# PY32F032xx register map
Vendor: Puya; Series: PY32F0; File version: 1.0.0
CPU: CM0+ r0p1, little endian, no MPU, no FPU, 4 interrupt priority bits
Registers are 32-bit, read-write, reset 0x0 unless marked. A register's access mark holds for its fields unless they carry their own. Offsets are from the block's base; [hi:lo] are bit positions.

## RTC — Real time clock
Base 0x40002800
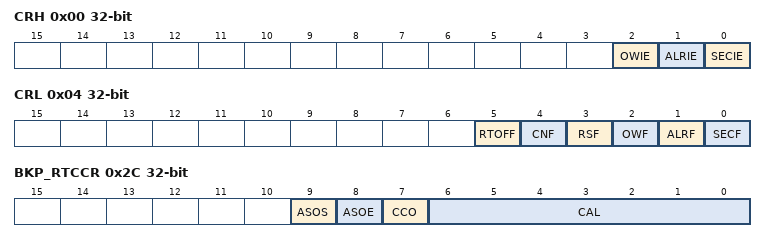
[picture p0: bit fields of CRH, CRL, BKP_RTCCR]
0x00 CRH — RTC Control Register High
  [2] OWIE — Overflow interrupt allow bits
  [1] ALRIE — Alarm interrupt allowed bits
  [0] SECIE — Seconds interrupt allowed bits
0x04 CRL — RTC Control Register Low
  [5] RTOFF ro — RTC operation OFF
  [4] CNF — Configuration flag
  [3] RSF — Registers synchronized flag
  [2] OWF — Overflow flag
  [1] ALRF — Alarm flag
  [0] SECF — Second flag
0x08 PRLH — RTC Prescaler Load Register High
  [5:0] PRL — RTC prescaler reload value high
0x0C PRLL — RTC Prescaler Load Register Low
  [15:0] PRL — RTC prescaler reload value high
0x10 DIVH — RTC Prescaler Divider Register High
  [3:0] RTC_DIV ro — RTC clock divider
    1=0; 2=1; 4=2; 8=3
0x14 DIVL — RTC Prescaler Divider Register Low
  [15:0] RTC_DIV ro — RTC clock divider
0x18 CNTH — RTC Counter Register High
  [15:0] RTC_CNT — RTC core counter
0x1C CNTL — RTC Counter Register Low
  [15:0] RTC_CNT — RTC core counter
0x20 ALRH — RTC Alarm Register High
  [15:0] ALR — RTC alarm value
0x24 ALRL — RTC Alarm Register Low
  [15:0] ALR — RTC alarm value
0x2C BKP_RTCCR
  [9] ASOS — Seconds/alarm pulse output select bits
  [8] ASOE — Seconds/alarm pulse output enable bit
  [7] CCO — Calibrate the clock output bits
  [6:0] CAL — Calibration value

## SPI1 — Serial peripheral interface
Base 0x40013000
Same registers: SPI2 0x40003800
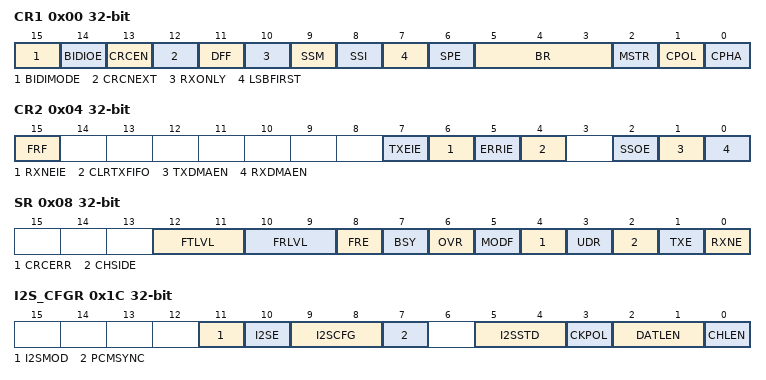
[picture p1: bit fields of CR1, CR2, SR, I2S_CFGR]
0x00 CR1 — control register 1
  [15] BIDIMODE — Bidirectional data mode enable
  [14] BIDIOE — Output enable in bidirectional mode
  [13] CRCEN — Hardware CRC calculation enable
  [12] CRCNEXT — Transmit CRC next
  [11] DFF — Data frame format
  [10] RXONLY — Receive only
  [9] SSM — Software slave management
  [8] SSI — Internal slave select
  [7] LSBFIRST — Frame Format
  [6] SPE — SPI Enable
  [5:3] BR — Baud Rate Control
    1=0; 2=1; 4=2
  [2] MSTR — Master Selection
  [1] CPOL — Clock Polarity
  [0] CPHA — Clock Phase
0x04 CR2 — control register 2
  [15] FRF
  [7] TXEIE — Tx buffer Empty Interrupt Enable
  [6] RXNEIE — RX buffer Not Empty Interrupt Enable
  [5] ERRIE — Error Interrupt Enable
  [4] CLRTXFIFO — Clear FIFO
  [2] SSOE — SS Output Enable
  [1] TXDMAEN — Tx buffer DMA enable
  [0] RXDMAEN — Rx buffer DMA enable
0x08 SR — status register
  [12:11] FTLVL ro — FIFO Transmission Level
    1=0; 2=1
  [10:9] FRLVL ro — FIFO Reception Level
    1=0; 2=1
  [8] FRE ro
  [7] BSY ro — Busy flag
  [6] OVR ro — Overrun flag
  [5] MODF — Mode fault
  [4] CRCERR — CRC error flag
  [3] UDR ro — Underrun flag
  [2] CHSIDE ro — Channel side
  [1] TXE ro — Transmit buffer Empty
  [0] RXNE ro — Receive buffer Not Empty
0x0C DR — data register
  [15:0] DR — Data Register
0x10 CRCPR — CRC polynomial register
  [15:0] CRCPOLY
0x14 RXCRCR
  [15:0] RXCRC — rcv crc reg
0x18 TXCRCR
  [15:0] TXCRC ro — tx crc reg
0x1C I2S_CFGR
  [11] I2SMOD — I2S mode selection
  [10] I2SE — I2S enable
  [9:8] I2SCFG — I2S configuration mode
    1=0; 2=1
  [7] PCMSYNC — PCM frame synchronization
  [5:4] I2SSTD — I2S standard selection
    1=0; 2=1
  [3] CKPOL — Steady state clock polarity
  [2:1] DATLEN — Data length to be transferred
    1=0; 2=1
  [0] CHLEN — Channel length (number of bits per audio channel)
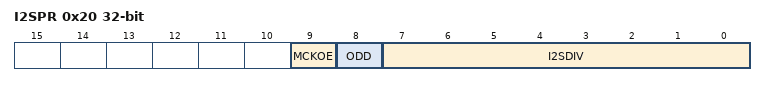
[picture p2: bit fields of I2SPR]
0x20 I2SPR — I2S prescaler register
  [9] MCKOE — Master clock output enable
  [8] ODD — Odd factor for the prescaler
  [7:0] I2SDIV — I2S linear prescaler

## SYSCFG — System configuration controller
Base 0x40010000
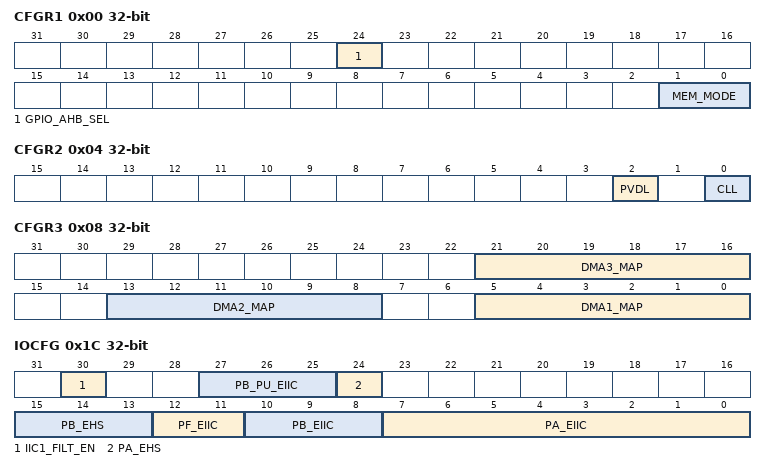
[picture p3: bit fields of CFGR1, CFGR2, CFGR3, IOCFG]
0x00 CFGR1 — SYSCFG configuration register1
  [24] GPIO_AHB_SEL
  [1:0] MEM_MODE
    1=0; 2=1
0x04 CFGR2 — SYSCFG configuration register2
  [2] PVDL, [0] CLL
0x08 CFGR3 — SYSCFG configuration register3
  [all] fields
    1=0; 2=1; 4=2; 8=3; 16=4; 32=5
  [21:16] DMA3_MAP
  [13:8] DMA2_MAP
  [5:0] DMA1_MAP
0x10 PA_ENS_REG
  [15:0] PA_ENS
0x14 PB_ENS_REG
  [15:0] PB_ENS
0x18 PF_ENS_REG
  [15:0] PF_ENS
0x1C IOCFG
  [30] IIC1_FILT_EN
  [27:25] PB_PU_EIIC
  [24] PA_EHS
  [15:13] PB_EHS
    1=0; 2=1; 4=2
  [12:11] PF_EIIC
    1=0; 2=1
  [10:8] PB_EIIC
    1=0; 2=1; 4=2
  [7:0] PA_EIIC
    1=0; 2=1; 4=2; 8=3; 16=4; 32=5; 64=6; 128=7
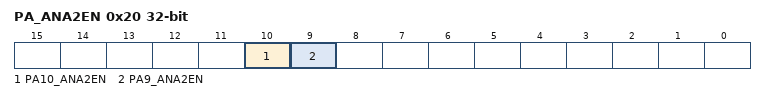
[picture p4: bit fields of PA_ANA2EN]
0x20 PA_ANA2EN
  [10] PA10_ANA2EN, [9] PA9_ANA2EN
0x2C TEST_DUMMY
  [7:0] DUMMY
